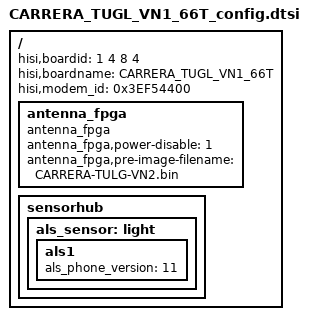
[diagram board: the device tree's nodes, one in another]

/**
 * Huawei Ltd.
 * PhosphorV660
 */


/include/ "CARRERA_TUGL_V4_66T_config.dtsi"

/ {
	hisi,boardid = <1 4 8 4 >;
	hisi,boardname = "CARRERA_TUGL_VN1_66T";
	hisi,modem_id = <0x3EF54400>;
	antenna_fpga{
		compatible = "antenna_fpga";
		antenna_fpga,power-disable = <1>;
		antenna_fpga,pre-image-filename = "CARRERA-TULG-VN2.bin";
		status = "ok";
	};
	sensorhub{
		als_sensor:light{
			als1{
				als_phone_version = <11>;
			};
		};
	};
};

